# IND83215A register map
Series: Verne; File version: A0
CPU: CM0 r0p1, selectable endian, no MPU, no FPU, 4 interrupt priority bits
Registers are 32-bit, read-write, no defined reset value unless marked. A register's access mark holds for its fields unless they carry their own. Offsets are from the block's base; [hi:lo] are bit positions; {n}, {i} and the like mark numbered series.

## GPIO — GPIO bit control and configuration
Base 0x50004400; register names take the prefix GPIO_
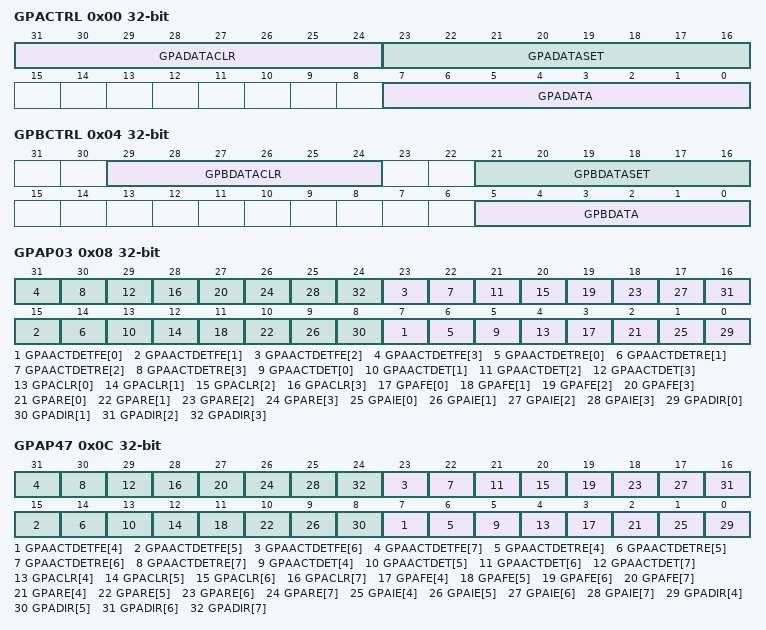
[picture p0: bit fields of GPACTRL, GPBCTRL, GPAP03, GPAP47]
0x00 GPACTRL — GPIO Port A Control Registers
  [31:24] GPADATACLR wo — Write-only register. Write 1 to clr the corresponding GPIO output data. Write 0 has no effects.
  [23:16] GPADATASET wo — Write-only register. Write 1 to set the corresponding GPIO output data. Write 0 has no effects.
  [7:0] GPADATA dual — Port A data. Read feedbacks the status of PORTs. Write to control the GPIO's output data.
0x04 GPBCTRL — GPIO Port B Control Registers
  [29:24] GPBDATACLR wo — Write-only register. Write 1 to clr the corresponding GPIO output data. Write 0 has no effects.
  [21:16] GPBDATASET wo — Write-only register. Write 1 to set the corresponding GPIO output data. Write 0 has no effects.
  [5:0] GPBDATA dual — Port B data. Read feedbacks the status of PORTs. Write to control the GPIO's output data.
0x08 GPAP03 — GPIO Port A Pin 0-3 Control
  [8n+7] GPAACTDETFE[{n}] ro (n=0..3) — PIN {n} activity fall status.
  [8n+6] GPAACTDETRE[{n}] ro (n=0..3) — PIN {n} activity rise status.
  [8n+5] GPAACTDET[{n}] ro (n=0..3) — Pin {n} activity interrupt.
  [8n+4] GPACLR[{n}] wo (n=0..3) — Pin {n} interrupt clear. Autoclear: includes a synchronous reset signal which clears the register on the cycle following write.
  [8n+3] GPAFE[{n}] (n=0..3) — Pin {n} falling edge enable.
  [8n+2] GPARE[{n}] (n=0..3) — Pin {n} rising edge enable.
  [8n+1] GPAIE[{n}] (n=0..3) — Pin {n} interrupt mask.
  [8n] GPADIR[{n}] (n=0..3) — Pin {n} output enable.
0x0C GPAP47 — GPIO Port A Pin 4-7 Control
  [8n-25] GPAACTDETFE[{n}] ro (n=4..7) — PIN {n} activity fall status.
  [8n-26] GPAACTDETRE[{n}] ro (n=4..7) — PIN {n} activity rise status.
  [8n-27] GPAACTDET[{n}] ro (n=4..7) — Pin {n} activity interrupt.
  [8n-28] GPACLR[{n}] wo (n=4..7) — Pin {n} interrupt clear. Autoclear: includes a synchronous reset signal which clears the register on the cycle following write.
  [8n-29] GPAFE[{n}] (n=4..7) — Pin {n} falling edge enable.
  [8n-30] GPARE[{n}] (n=4..7) — Pin {n} rising edge enable.
  [8n-31] GPAIE[{n}] (n=4..7) — Pin {n} interrupt mask.
  [8n-32] GPADIR[{n}] (n=4..7) — Pin {n} output enable.
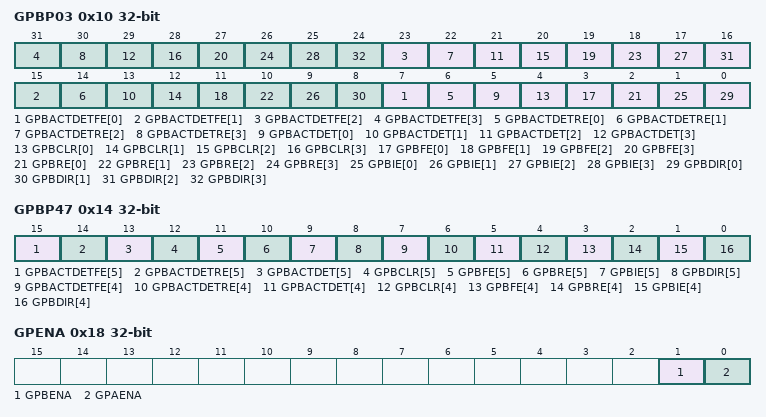
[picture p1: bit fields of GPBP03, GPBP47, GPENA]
0x10 GPBP03 — GPIO Port B Pin 0-3 Control
  [8n+7] GPBACTDETFE[{n}] ro (n=0..3) — PIN {n} activity fall status.
  [8n+6] GPBACTDETRE[{n}] ro (n=0..3) — PIN {n} activity rise status.
  [8n+5] GPBACTDET[{n}] ro (n=0..3) — Pin {n} activity interrupt.
  [8n+4] GPBCLR[{n}] wo (n=0..3) — Pin {n} interrupt clear. Autoclear: includes a synchronous reset signal which clears the register on the cycle following write.
  [8n+3] GPBFE[{n}] (n=0..3) — Pin {n} falling edge enable.
  [8n+2] GPBRE[{n}] (n=0..3) — Pin {n} rising edge enable.
  [8n+1] GPBIE[{n}] (n=0..3) — Pin {n} interrupt mask.
  [8n] GPBDIR[{n}] (n=0..3) — Pin {n} output enable.
0x14 GPBP47 — GPIO Port B Pin 4-7 Control
  [15] GPBACTDETFE[5] ro — PIN 5 activity fall status.
  [14] GPBACTDETRE[5] ro — PIN 5 activity rise status.
  [13] GPBACTDET[5] ro — Pin 5 activity interrupt.
  [12] GPBCLR[5] wo — Pin 5 interrupt clear. Autoclear: includes a synchronous reset signal which clears the register on the cycle following write.
  [11] GPBFE[5] — Pin 5 falling edge enable.
  [10] GPBRE[5] — Pin 5 rising edge enable.
  [9] GPBIE[5] — Pin 5 interrupt mask.
  [8] GPBDIR[5] — Pin 5 output enable.
  [7] GPBACTDETFE[4] ro — PIN 4 activity fall status.
  [6] GPBACTDETRE[4] ro — PIN 4 activity rise status.
  [5] GPBACTDET[4] ro — Pin 4 activity interrupt.
  [4] GPBCLR[4] wo — Pin 4 interrupt clear. Autoclear: includes a synchronous reset signal which clears the register on the cycle following write.
  [3] GPBFE[4] — Pin 4 falling edge enable.
  [2] GPBRE[4] — Pin 4 rising edge enable.
  [1] GPBIE[4] — Pin 4 interrupt mask.
  [0] GPBDIR[4] — Pin 4 output enable.
0x18 GPENA — GPIO Port Enables
  [1] GPBENA, [0] GPAENA
